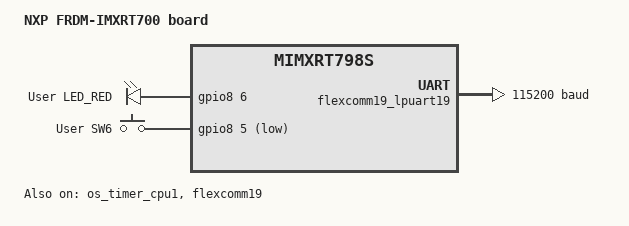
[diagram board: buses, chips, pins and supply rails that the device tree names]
/*
 * Copyright 2026 NXP
 *
 * SPDX-License-Identifier: Apache-2.0
 */

/dts-v1/;

#include <nxp/imxrt/imxrt7xx/nxp_rt7xx_cm33_cpu1.dtsi>
#include <zephyr/dt-bindings/input/input-event-codes.h>
#include "frdm_imxrt700-pinctrl.dtsi"

/ {
	compatible = "nxp,mimxrt798s";
	model = "NXP FRDM-IMXRT700 board";

	aliases {
		led0 = &red_led;
		sw0 = &user_button_1;
	};

	chosen {
		zephyr,flash = &sram_code;
		zephyr,sram = &sram3;
		zephyr,console = &flexcomm19_lpuart19;
		zephyr,shell-uart = &flexcomm19_lpuart19;
	};

	leds {
		compatible = "gpio-leds";

		red_led: led_0 {
			gpios = <&gpio8 6 GPIO_ACTIVE_HIGH>;
			label = "User LED_RED";
			status = "okay";
		};
	};

	gpio_keys {
		compatible = "gpio-keys";

		user_button_1: button_0 {
			label = "User SW6";
			gpios = <&gpio8 5 GPIO_ACTIVE_LOW>;
			zephyr,code = <INPUT_KEY_0>;
			status = "okay";
		};
	};
};

/*
 * RT700-FRDM board cm33_cpu1 uses OS timer as the kernel timer
 * In case we need to switch to SYSTICK timer, then
 * replace &os_timer with &systick
 */
&os_timer_cpu1 {
	wakeup-source;
	status = "okay";
};

&flexcomm19 {
	status = "okay";
};

&flexcomm19_lpuart19 {
	current-speed = <115200>;
	pinctrl-0 = <&pinmux_flexcomm19_lpuart>;
	pinctrl-names = "default";
	status = "okay";
};

&gpio8 {
	status = "okay";
};
